# XMC4300 register map
Vendor: Infineon; File version: 0.5.1 (Superset device XMC4800)
CPU: CM4 r2p0, little endian, MPU, FPU, 6 interrupt priority bits
Registers are 32-bit, read-write, reset 0x0 unless marked. A register's access mark holds for its fields unless they carry their own. Offsets are from the block's base; [hi:lo] are bit positions; {n}, {i} and the like mark numbered series.

## DLR — DMA Line Router
Base 0x50004900
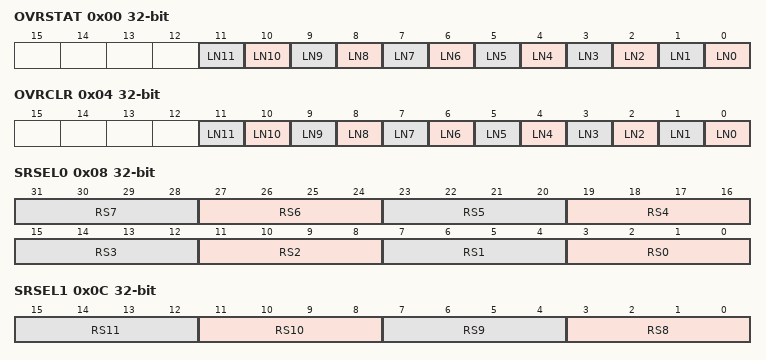
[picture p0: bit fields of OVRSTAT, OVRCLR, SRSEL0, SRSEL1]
0x00 OVRSTAT ro — Overrun Status
  [n] LN{n} (n=0..11) — Line {n} Overrun Status
0x04 OVRCLR wo — Overrun Clear
  [n] LN{n} (n=0..11) — Line {n} Overrun Status Clear
0x08 SRSEL0 — Service Request Selection 0
  [4n+3:4n] RS{n} (n=0..7) — Request Source for Line {n}
0x0C SRSEL1 — Service Request Selection 1
  [4n-29:4n-32] RS{n} (n=8..11) — Request Source for Line {n}
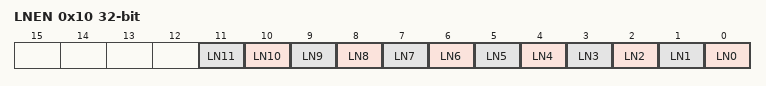
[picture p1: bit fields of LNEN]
0x10 LNEN — Line Enable
  [all] fields
    0=Disables the line; 1=Enables the line and resets a pending request
  [n] LN{n} (n=0..11) — Line {n} Enable

## ERU0 — Event Request Unit 0
Base 0x50004800
Same registers: ERU1 0x40044000
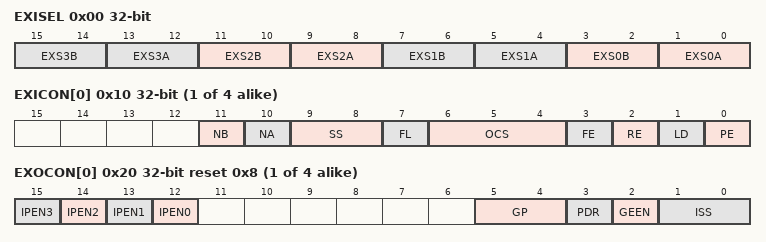
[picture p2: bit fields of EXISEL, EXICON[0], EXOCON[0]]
0x00 EXISEL — Event Input Select
  [4n+3:4n+2] EXS{n}B (n=0..3) — Event Source Select for B{n} (ERS{n})
    {v}=Input ERU_{n}B{v} is selected (v=0..3)
  [4n+1:4n] EXS{n}A (n=0..3) — Event Source Select for A{n} (ERS{n})
    {v}=Input ERU_{n}A{v} is selected (v=0..3)
{0x10+4i} EXICON[{i}] (i=0..3) — Event Input Control
  [11] NB — Input B Negation Select for ERSx
    0=Input B is used directly; 1=Input B is inverted
  [10] NA — Input A Negation Select for ERSx
    0=Input A is used directly; 1=Input A is inverted
  [9:8] SS — Input Source Select for ERSx
    0=Input A without additional combination; 1=Input B without additional combination; 2=Input A OR input B; 3=Input A AND input B
  [7] FL — Status Flag for ETLx
    0=The enabled edge event has not been detected; 1=The enabled edge event has been detected
  [6:4] OCS — Output Channel Select for ETLx Output Trigger Pulse
    {v}=Trigger pulses are sent to OGU{v} (v=0..3)
  [3] FE — Falling Edge Detection Enable ETLx
    0=A falling edge is not considered as edge event; 1=A falling edge is considered as edge event
  [2] RE — Rising Edge Detection Enable ETLx
    0=A rising edge is not considered as edge event; 1=A rising edge is considered as edge event
  [1] LD — Rebuild Level Detection for Status Flag for ETLx
    0=The status flag FL is not cleared by hardware and is used as "sticky" bit. Once set, it is not influenced by any edge until it becomes cleared by software.; 1=The status flag FL rebuilds a level detection of the desired event. It becomes automatically set with a rising edge if RE = 1 or with a falling edge if FE = 1. It becomes automatically cleared with a rising edge if RE = 0 or with a falling edge if FE = 0.
  [0] PE — Output Trigger Pulse Enable for ETLx
    0=The trigger pulse generation is disabled; 1=The trigger pulse generation is enabled
{0x20+4i} EXOCON[{i}] (i=0..3) access per field reset 0x8 — Event Output Trigger Control
  [n+12] IPEN{n} rw (n=0..3) — Pattern Detection Enable for ETL{n}
    0=Flag EXICONx.FL is excluded from the pattern detection; 1=Flag EXICONx.FL is included in the pattern detection
  [5:4] GP rw — Gating Selection for Pattern Detection Result
    0=ERU_GOUTy is always disabled and ERU_IOUTy can not be activated; 1=ERU_GOUTy is always enabled and ERU_IOUTy becomes activated with each activation of ERU_TOUTy; 2=ERU_GOUTy is equal to ERU_PDOUTy and ERU_IOUTy becomes activated with an activation of ERU_TOUTy while the desired pattern is detected (pattern match PDR = 1); 3=ERU_GOUTy is inverted to ERU_PDOUTy and ERU_IOUTy becomes activated with an activation of ERU_TOUTy while the desired pattern is not detected (pattern miss PDR = 0)
  [3] PDR ro — Pattern Detection Result Flag
    0=A pattern miss is detected; 1=A pattern match is detected
  [2] GEEN rw — Gating Event Enable
    0=The event detection is disabled; 1=The event detection is enabled
  [1:0] ISS rw — Internal Trigger Source Selection
    0=The peripheral trigger function is disabled; 1=Input ERU_OGUy1 is selected; 2=Input ERU_OGUy2 is selected; 3=Input ERU_OGUy3 is selected

## Notices in the file
Copyright (c) 2016, Infineon Technologies AG
All rights reserved.
Redistribution and use in source and binary forms, with or without modification,are permitted provided that the
following conditions are met:
Redistributions of source code must retain the above copyright notice, this list of conditions and the following
disclaimer.
Redistributions in binary form must reproduce the above copyright notice, this list of conditions and the following
disclaimer in the documentation and/or other materials provided with the distribution.
Neither the name of the copyright holders nor the names of its contributors may be used to endorse or promote
products derived from this software without specific prior written permission.
THIS SOFTWARE IS PROVIDED BY THE COPYRIGHT HOLDERS AND CONTRIBUTORS "AS IS" AND ANY EXPRESS OR IMPLIED WARRANTIES,
INCLUDING, BUT NOT LIMITED TO, THE IMPLIED WARRANTIES OF MERCHANTABILITY AND FITNESS FOR A PARTICULAR PURPOSE ARE
DISCLAIMED. IN NO EVENT SHALL THE COPYRIGHT HOLDER OR CONTRIBUTORS BE LIABLE  FOR ANY DIRECT, INDIRECT, INCIDENTAL,
SPECIAL, EXEMPLARY, OR CONSEQUENTIAL DAMAGES (INCLUDING, BUT NOT LIMITED TO, PROCUREMENT OF SUBSTITUTE GOODS OR
SERVICES; LOSS OF USE, DATA, OR PROFITS; OR BUSINESS INTERRUPTION) HOWEVER CAUSED AND ON ANY THEORY OF LIABILITY,
WHETHER IN CONTRACT, STRICT LIABILITY,OR TORT (INCLUDING NEGLIGENCE OR OTHERWISE) ARISING IN ANY WAY OUT OF THE USE
OF THIS SOFTWARE, EVEN IF ADVISED OF THE POSSIBILITY OF SUCH DAMAGE.
